# f29h85x_rtdma_mpu_regs register map
Vendor: Texas Instruments
Peripheral module from a debugger description file (folder HSM).
Registers are 32-bit, read-write, no defined reset value unless marked. A register's access mark holds for its fields unless they carry their own. Offsets are as the file gives them; lines under a group give offsets from that group; [hi:lo] are bit positions; {n}, {i} and the like mark numbered series; 'fields as' and 'values as' point back to an identical list; <NAME> marks a mode.

## RTDMA_MPU_REGS — RTDMA MPU Registers
{0x0+0x20*i} RTDMA_MPU_REGS_RegisterFile0[{i}] (i=0..15) group
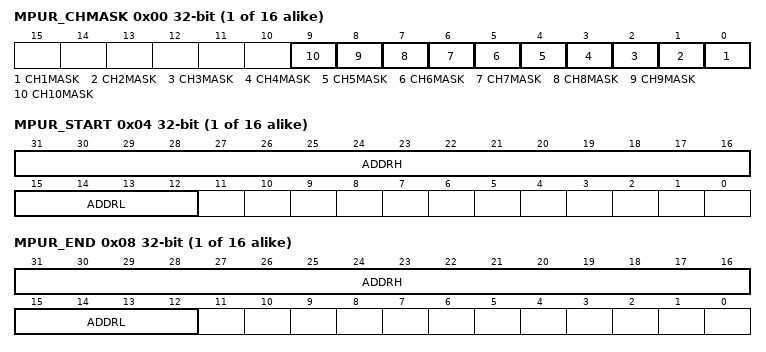
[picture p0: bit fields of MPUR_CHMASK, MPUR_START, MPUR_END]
  0x00 MPUR_CHMASK — MPU Region Configuration
    [n-1] CH{n}MASK (n=1..10) — MPU region channel mask Channel {n}
  0x04 MPUR_START — MPU Region Start Address
    [31:16] ADDRH — Upper Start Address
    [15:12] ADDRL — Lower Start Address
  0x08 MPUR_END — MPU Region End Address
    [31:16] ADDRH — Upper End Address
    [15:12] ADDRL — Lower End Address
  0x0C MPUR_LOCK — MPU Temporary Lock
    [0] LOCK — Temporary Lock
  0x10 MPUR_COMMIT — MPU Permanent Commit
    [0] COMMIT — Permanent Commit
  0x14 MPUR_ACCESS — MPU Region R/W Access Permissions
    [1:0] ACCESS — Region Access Permissions
0x800 MPUCTRL — MPU Control Register
  [0] MPUEN — Enable MPU function
0x820 MPUCFG_LOCK — Channel Configuration Temporary Lock
  [0] LOCK — Temporary Lock
0x824 MPUCFG_COMMIT — Channel Configuration Permanent Commit
  [0] COMMIT — Permanent Commit
